# ISS_ISP5_SYS2 register map
Vendor: Texas Instruments
Peripheral module from a debugger description file (folder omap4430).
Registers are 32-bit, access not given, reset 0x0 unless marked. A register's access mark holds for its fields unless they carry their own. Offsets are as the file gives them; lines under a group give offsets from that group; [hi:lo] are bit positions; {n}, {i} and the like mark numbered series; 'fields as' and 'values as' point back to an identical list; <NAME> marks a mode.

## ISS_ISP5_SYS2
0x00 ISP5_KEY_EN1 ro — IPIPE eFuse enable.
  [0] KEY1_EN — eFuse enable Equals 1 when ISP5_EFUSE3_EN = 1 or 0 otherwise.
    1=KEY1_EN_1_r (Enable); 0=KEY1_EN_0_r (Disable)
0x04 ISP5_KEY_EN2 ro reset 0x1 — ISIF eFuse enable.
  [0] KEY1_EN — eFuse enable Equals 1 when ISP5_EFUSE1_EN = 1 or 0 otherwise.
    1=KEY1_EN_1_r (Enable); 0=KEY1_EN_0_r (Disable)
0x08 ISP5_KEY_EN3 ro — ISIF eFuse enable.
  [0] KEY_EN — eFuse enable Equals 1 when ISP5_EFUSE3_EN = 1 or 0 otherwise.
    1=KEY_EN_1_r (Enable); 0=KEY_EN_0_r (Disable)
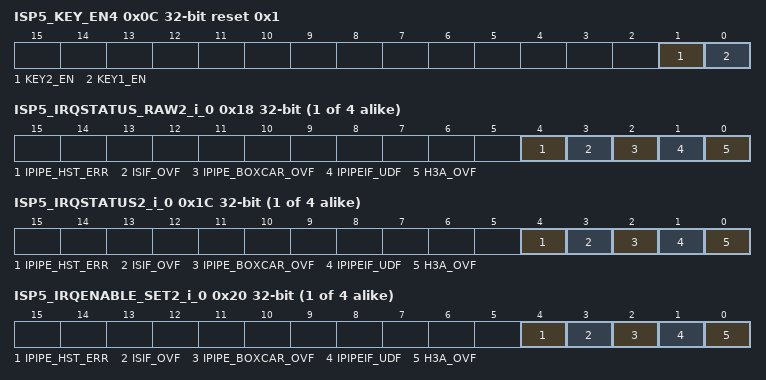
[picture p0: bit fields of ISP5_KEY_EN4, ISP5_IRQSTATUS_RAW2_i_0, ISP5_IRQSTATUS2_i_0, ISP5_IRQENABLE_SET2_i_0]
0x0C ISP5_KEY_EN4 ro reset 0x1 — IPIPEIF eFuse enable.
  [1] KEY2_EN — eFuse enable Equals 1 when ISP5_EFUSE4_EN = 1 or 0 otherwise.
    1=KEY2_EN_1_r (Enable); 0=KEY2_EN_0_r (Disable)
  [0] KEY1_EN — eFuse enable Equals 1 when ISP5_EFUSE1_EN = 1 or 0 otherwise.
    1=KEY1_EN_1_r (Enable); 0=KEY1_EN_0_r (Disable)
0x10 ISP5_KEY_EN5 ro — H3A eFuse enable.
  [0] KEY_EN — eFuse enable Equals 1 when ISP5_EFUSE2_EN = 1 or 0 otherwise.
    1=KEY_EN_1_r (Enable); 0=KEY_EN_0_r (Disable)
0x14 ISP5_KEY_EN6 ro — H3A eFuse enable.
  fields as ISP5_KEY_EN3
{0x18+0x10*i} ISP5_IRQSTATUS_RAW2_i_{i} (i=0..3) — Per-event raw interrupt status vector. Raw status is set even if event is not enabled. Write 1 to set the (raw) status, mostly for debug. Overflow / underflow errors are not recoverable at ISP level, a software reset is required at ISS level. The ISP outputs 4 interrupt lines ISP5_IRQ0 to ISP5_IRQ3. Any internal ISP event can be merged on the 4 lines. A same event must be enabled on only one interrupt line.
  [4] IPIPE_HST_ERR — IPIPE HISTOGRAM memory read error This error will happen when the histogram data is not read fast enough by the MPU or the DMA. When the data is read with the MPU, one need to pay attention to clear the ISP5_CTRL[26] HST_RD_CHK bit immediately after reading the last data, else this event will be set. (access RW W1toSet)
    0=IPIPE_HST_ERR_0_w (No action); 1=IPIPE_HST_ERR_1_w (Set event (debug)); 1=IPIPE_HST_ERR_1_r (Event pending); 0=IPIPE_HST_ERR_0_r (No event pending)
  [3] ISIF_OVF — ISIF module overflow (access RW W1toSet)
    0=ISIF_OVF_0_w (No action); 1=ISIF_OVF_1_w (Set event (debug)); 1=ISIF_OVF_1_r (Event pending); 0=ISIF_OVF_0_r (No event pending)
  [2] IPIPE_BOXCAR_OVF — IPIPE BOXCAR module overflow (access RW W1toSet)
    0=IPIPE_BOXCAR_OVF_0_w (No action); 1=IPIPE_BOXCAR_OVF_1_w (Set event (debug)); 1=IPIPE_BOXCAR_OVF_1_r (Event pending); 0=IPIPE_BOXCAR_OVF_0_r (No event pending)
  [1] IPIPEIF_UDF — IPIPEIF module underflow interrupt (access RW W1toSet)
    0=IPIPEIF_UDF_0_w (No action); 1=IPIPEIF_UDF_1_w (Set event (debug)); 1=IPIPEIF_UDF_1_r (Event pending); 0=IPIPEIF_UDF_0_r (No event pending)
  [0] H3A_OVF — H3A module overflow interrupt. (access RW W1toSet)
    0=H3A_OVF_0_w (No action); 1=H3A_OVF_1_w (Set event (debug)); 1=H3A_OVF_1_r (Event pending); 0=H3A_OVF_0_r (No event pending)
{0x1C+0x10*i} ISP5_IRQSTATUS2_i_{i} (i=0..3) — Per-event 'enabled' interrupt status vector. Enabled status is not set unless event is enabled. Write 1 to clear the status after interrupt has been serviced (raw status gets cleared, that is, even if not enabled). Overflow / underflow errors are not recoverable at ISP level, a software reset is required at ISS level. The ISP outputs 4 interrupt lines ISP5_IRQ0 to ISP5_IRQ3. Any internal ISP event can be merged on the 4 lines. A same event must be enabled on only one interrupt line.
  [4] IPIPE_HST_ERR — IPIPE HISTOGRAM memory read error This error will happen when the histogram data is not read fast enough by either the MPU or the DMA. (access RW W1toClr)
    0=IPIPE_HST_ERR_0_w (No action); 1=IPIPE_HST_ERR_1_w (Clear (raw) event); 1=IPIPE_HST_ERR_1_r (Event pending); 0=IPIPE_HST_ERR_0_r (No (enabled) event pending)
  [3] ISIF_OVF — ISIF module overflow (access RW W1toClr)
    0=ISIF_OVF_0_w (No action); 1=ISIF_OVF_1_w (Clear (raw) event); 1=ISIF_OVF_1_r (Event pending); 0=ISIF_OVF_0_r (No (enabled) event pending)
  [2] IPIPE_BOXCAR_OVF — IPIPE BOXCAR module overflow Overflow errors are not recoverable at ISP level, a software reset is required at ISS level. (access RW W1toClr)
    0=IPIPE_BOXCAR_OVF_0_w (No action); 1=IPIPE_BOXCAR_OVF_1_w (Clear (raw) event); 1=IPIPE_BOXCAR_OVF_1_r (Event pending); 0=IPIPE_BOXCAR_OVF_0_r (No (enabled) event pending)
  [1] IPIPEIF_UDF — IPIPEIF module underflow interrupt (access RW W1toClr)
    0=IPIPEIF_UDF_0_w (No action); 1=IPIPEIF_UDF_1_w (Clear (raw) event); 1=IPIPEIF_UDF_1_r (Event pending); 0=IPIPEIF_UDF_0_r (No (enabled) event pending)
  [0] H3A_OVF — H3A module overflow interrupt. Overflow errors are not recoverable at ISP level, a software reset is required at ISS level. (access RW W1toClr)
    0=H3A_OVF_0_w (No action); 1=H3A_OVF_1_w (Clear (raw) event); 1=H3A_OVF_1_r (Event pending); 0=H3A_OVF_0_r (No (enabled) event pending)
{0x20+0x10*i} ISP5_IRQENABLE_SET2_i_{i} (i=0..3) — Per-event interrupt enable bit vector. Write 1 to set (enable interrupt). Readout equal to corresponding _CLR register. Overflow / underflow errors are not recoverable at ISP level, a software reset is required at ISS level. The ISP outputs 4 interrupt lines ISP5_IRQ0 to ISP5_IRQ3. Any internal ISP event can be merged on the 4 lines. A same event must be enabled on only one interrupt line.
  [4] IPIPE_HST_ERR — IPIPE HISTOGRAM memory read error This error will happen when the histogram data is not read fast enough by either the MPU or the DMA. (access RW W1toSet)
  [3] ISIF_OVF — ISIF module overflow (access RW W1toSet)
  [2] IPIPE_BOXCAR_OVF — IPIPE BOXCAR module overflow (access RW W1toSet)
  [1] IPIPEIF_UDF — IPIPEIF module underflow interrupt (access RW W1toSet)
  [0] H3A_OVF — H3A module overflow interrupt. (access RW W1toSet)
    0=H3A_OVF_0_w (No action); 1=H3A_OVF_1_w (Enable interrupt); 1=H3A_OVF_1_r (Interrupt enabled); 0=H3A_OVF_0_r (Interrupt disabled)
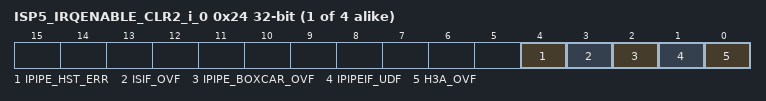
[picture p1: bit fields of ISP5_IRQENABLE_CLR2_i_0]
{0x24+0x10*i} ISP5_IRQENABLE_CLR2_i_{i} (i=0..3) — Per-event interrupt enable bit vector. Write 1 to clear (disable interrupt). Readout equal to corresponding _SET register. Overflow / underflow errors are not recoverable at ISP level, a software reset is required at ISS level. The ISP outputs 4 interrupt lines ISP5_IRQ0 to ISP5_IRQ3. Any internal ISP event can be merged on the 4 lines. A same event must be enabled on only one interrupt line.
  [4] IPIPE_HST_ERR — IPIPE HISTOGRAM memory read error This error will happen when the histogram data is not read fast enough by either the MPU or the DMA. (access RW W1toClr)
    0=IPIPE_HST_ERR_0_w (No action); 1=IPIPE_HST_ERR_1_w (Disable Interrupt); 1=IPIPE_HST_ERR_1_r (Interrupt enabled); 0=IPIPE_HST_ERR_0_r (Interrupt disabled)
  [3] ISIF_OVF — ISIF module overflow (access RW W1toClr)
    0=ISIF_OVF_0_w (No action); 1=ISIF_OVF_1_w (Disable Interrupt); 1=ISIF_OVF_1_r (Interrupt enabled); 0=ISIF_OVF_0_r (Interrupt disabled)
  [2] IPIPE_BOXCAR_OVF — IPIPE BOXCAR module overflow (access RW W1toClr)
    0=IPIPE_BOXCAR_OVF_0_w (No action); 1=IPIPE_BOXCAR_OVF_1_w (Disable Interrupt); 1=IPIPE_BOXCAR_OVF_1_r (Interrupt enabled); 0=IPIPE_BOXCAR_OVF_0_r (Interrupt disabled)
  [1] IPIPEIF_UDF — IPIPEIF module underflow interrupt (access RW W1toClr)
    0=IPIPEIF_UDF_0_w (No action); 1=IPIPEIF_UDF_1_w (Disable Interrupt); 1=IPIPEIF_UDF_1_r (Interrupt enabled); 0=IPIPEIF_UDF_0_r (Interrupt disabled)
  [0] H3A_OVF — H3A module overflow interrupt. (access RW W1toClr)
    0=H3A_OVF_0_w (No action); 1=H3A_OVF_1_w (Disable Interrupt); 1=H3A_OVF_1_r (Interrupt enabled); 0=H3A_OVF_0_r (Interrupt disabled)
